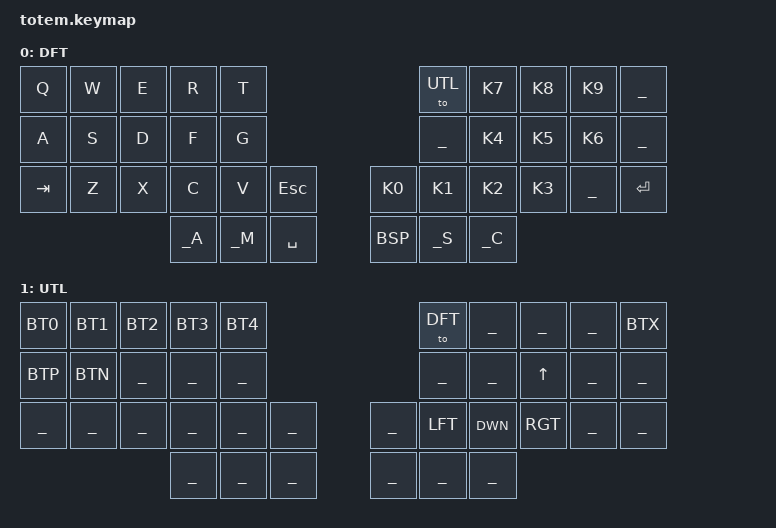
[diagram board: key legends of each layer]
//
//                                                        ▀▀▀▀▀     ▀▀▀▀▀          ▀▀█▀▀
//                                                        ▄▀▀▀▄  ▄  ▄▀▀▀▄  ▄  ▄▀▀▀▄  █  ▄▀▀▀▄
//                                                        █   █  █  █   █  █  █   █  █  █   █
//                                                         ▀▀▀   █   ▀▀▀   █   ▀▀▀   ▀   ▀▀▀
//                                                               █      ▄▄▄█▄▄▄    █   █
//                                                               ▀      █  █  █     █▄█
//                                                             ▀▀▀▀▀    █  █  █      ▀
//                                                                      ▀  ▀  ▀
//
// ▄▄▄▄▄▄▄▄▄▄▄▄▄▄▄▄▄▄▄▄▄▄▄▄▄▄▄▄▄▄▄▄▄▄▄▄▄▄▄▄▄▄▄▄▄▄▄▄▄▄▄▄▄▄▄▄▄▄▄▄▄▄▄▄▄▄▄▄▄▄▄▄▄▄▄▄▄▄▄▄▄▄▄▄▄▄▄▄▄▄▄▄▄▄▄▄▄▄▄▄▄▄▄▄▄▄▄▄▄▄▄▄▄▄▄▄▄▄▄▄▄▄▄▄▄▄▄▄▄▄▄▄▄▄▄▄▄▄▄▄▄▄▄▄▄▄▄▄▄
#include "shorteners.dtsi"
#include <behaviors.dtsi>
#include <dt-bindings/zmk/keys.h>
#include <dt-bindings/zmk/bt.h>
#include <dt-bindings/zmk/outputs.h>

#define DFT 0
#define UTL 1

#include "behaviors.dtsi"


/ {
	keymap {
		compatible = "zmk,keymap";
// ▄▄▄▄▄▄▄▄▄▄▄▄▄▄▄▄▄▄▄▄▄▄▄▄▄▄▄▄▄▄▄▄▄▄▄▄▄▄▄▄▄▄▄▄▄▄▄▄▄▄▄▄▄▄▄▄▄▄▄▄▄▄▄▄▄▄▄▄▄▄▄▄▄▄▄▄▄▄▄▄▄▄▄▄▄▄▄▄▄▄▄▄▄▄▄▄▄▄▄▄▄▄▄▄▄▄▄▄▄▄▄▄▄▄▄▄▄▄▄▄▄▄▄▄▄▄▄▄▄▄▄▄▄▄▄▄▄▄▄▄▄▄▄▄▄▄▄▄▄
		Default {
//	┏━━━━━━━━━━━━━━━━━━━━━━━━━━━━━━━━━━━━━━┓
display-name= "DFT"								;
//	┗━━━━━━━━━━━━━━━━━━━━━━━━━━━━━━━━━━━━━━┛
//					┏━━━━━━━━━━━┳━━━━━━━━━━━┳━━━━━━━━━━━┳━━━━━━━━━━━┳━━━━━━━━━━━┓									┏━━━━━━━━━━━┳━━━━━━━━━━━┳━━━━━━━━━━━┳━━━━━━━━━━━┳━━━━━━━━━━━┓
//					┃				┃				┃				┃				┃				┃									┃				┃				┃				┃				┃				┃
//					┣━━━━━━━━━━━╋━━━━━━━━━━━╋━━━━━━━━━━━╋━━━━━━━━━━━╋━━━━━━━━━━━┫									┣━━━━━━━━━━━╋━━━━━━━━━━━╋━━━━━━━━━━━╋━━━━━━━━━━━╋━━━━━━━━━━━┫
//					┃				┃				┃				┃				┃				┃									┃				┃				┃				┃				┃				┃
//	┏━━━━━━━━━━━╋━━━━━━━━━━━╋━━━━━━━━━━━╋━━━━━━━━━━━╋━━━━━━━━━━━╋━━━━━━━━━━━┫									┣━━━━━━━━━━━╋━━━━━━━━━━━╋━━━━━━━━━━━╋━━━━━━━━━━━╋━━━━━━━━━━━╋━━━━━━━━━━━┓
//	┃				┃				┃				┃				┃				┃				┃									┃				┃				┃				┃				┃				┃				┃
//	┗━━━━━━━━━━━┻━━━━━━━━━━━┻━━━━━━━━━━━┗━━━━━━━━━━━╋━━━━━━━━━━━╋━━━━━━━━━━━┫━━━━━━━━━━━┓		┏━━━━━━━━━━━┣━━━━━━━━━━━╋━━━━━━━━━━━╋━━━━━━━━━━━┛━━━━━━━━━━━┻━━━━━━━━━━━┻━━━━━━━━━━━┛
//																	┃				┃				┃				┃	┃				┃				┃				┃
//																	┗━━━━━━━━━━━┻━━━━━━━━━━━┻━━━━━━━━━━━┛	┗━━━━━━━━━━━┻━━━━━━━━━━━┻━━━━━━━━━━━┛
			bindings = <
// ╷				╷				╷				╷				╷				╷				╷				╷	╷				╷				╷				╷				╷				╷				╷				╷
//
						&kp Q			&kp W			&kp E			&kp R			&kp T												&to UTL		&kp K7		&kp K8		&kp K9		___
						&kp A			&kp S			&kp D			&kp F			&kp G												___ 			&kp K4		&kp K5		&kp K6		___
		&kp TAB		&kp Z			&kp X			&kp C			&kp V			&kp ESC											&kp K0		&kp K1		&kp K2		&kp K3		___		&kp RET
																		&kp _A		&kp _M		&kp SPC			&kp BSP		&kp _S		&kp _C
			>;
		}; // end default
// ▄▄▄▄▄▄▄▄▄▄▄▄▄▄▄▄▄▄▄▄▄▄▄▄▄▄▄▄▄▄▄▄▄▄▄▄▄▄▄▄▄▄▄▄▄▄▄▄▄▄▄▄▄▄▄▄▄▄▄▄▄▄▄▄▄▄▄▄▄▄▄▄▄▄▄▄▄▄▄▄▄▄▄▄▄▄▄▄▄▄▄▄▄▄▄▄▄▄▄▄▄▄▄▄▄▄▄▄▄▄▄▄▄▄▄▄▄▄▄▄▄▄▄▄▄▄▄▄▄▄▄▄▄▄▄▄▄▄▄▄▄▄▄▄▄▄▄▄▄
		Utils {
//	┏━━━━━━━━━━━━━━━━━━━━━━━━━━━━━━━━━━━━━━┓
display-name= "UTL"								;
//	┗━━━━━━━━━━━━━━━━━━━━━━━━━━━━━━━━━━━━━━┛
//					┏━━━━━━━━━━━┳━━━━━━━━━━━┳━━━━━━━━━━━┳━━━━━━━━━━━┳━━━━━━━━━━━┓									┏━━━━━━━━━━━┳━━━━━━━━━━━┳━━━━━━━━━━━┳━━━━━━━━━━━┳━━━━━━━━━━━┓
//					┃				┃				┃				┃				┃				┃									┃				┃				┃				┃				┃				┃
//					┣━━━━━━━━━━━╋━━━━━━━━━━━╋━━━━━━━━━━━╋━━━━━━━━━━━╋━━━━━━━━━━━┫									┣━━━━━━━━━━━╋━━━━━━━━━━━╋━━━━━━━━━━━╋━━━━━━━━━━━╋━━━━━━━━━━━┫
//					┃				┃				┃				┃				┃				┃									┃				┃				┃				┃				┃				┃
//	┏━━━━━━━━━━━╋━━━━━━━━━━━╋━━━━━━━━━━━╋━━━━━━━━━━━╋━━━━━━━━━━━╋━━━━━━━━━━━┫									┣━━━━━━━━━━━╋━━━━━━━━━━━╋━━━━━━━━━━━╋━━━━━━━━━━━╋━━━━━━━━━━━╋━━━━━━━━━━━┓
//	┃				┃				┃				┃				┃				┃				┃									┃				┃				┃				┃				┃				┃				┃
//	┗━━━━━━━━━━━┻━━━━━━━━━━━┻━━━━━━━━━━━┗━━━━━━━━━━━╋━━━━━━━━━━━╋━━━━━━━━━━━┫━━━━━━━━━━━┓		┏━━━━━━━━━━━┣━━━━━━━━━━━╋━━━━━━━━━━━╋━━━━━━━━━━━┛━━━━━━━━━━━┻━━━━━━━━━━━┻━━━━━━━━━━━┛
//																	┃				┃				┃				┃	┃				┃				┃				┃
//																	┗━━━━━━━━━━━┻━━━━━━━━━━━┻━━━━━━━━━━━┛	┗━━━━━━━━━━━┻━━━━━━━━━━━┻━━━━━━━━━━━┛
			bindings = <
// ╷				╷				╷				╷				╷				╷				╷				╷	╷				╷				╷				╷				╷				╷				╷				╷
//
						BT0		   BT1		   BT2		   BT3		   BT4											   &to DFT		___			___			___			BTX
						BTP		   BTN	   	___			___			___												___			___			&kp UP		___			___
		___			___			___			___			___			___												___			&kp LFT		&kp DWN		&kp RGT		___			___
																		___			___			___				___			___			___
			>;
		}; // end utils

	}; // end keymap
};
